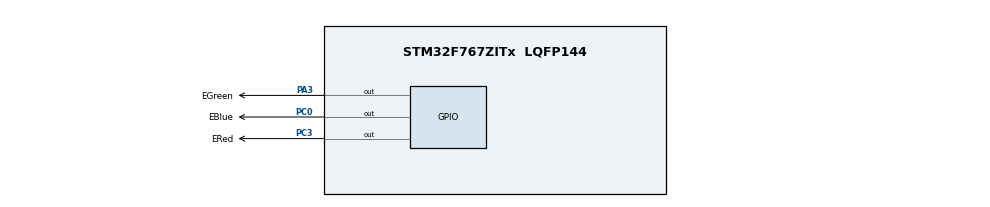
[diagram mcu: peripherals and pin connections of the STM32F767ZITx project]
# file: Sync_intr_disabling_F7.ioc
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FREERTOS.Tasks01=defaultTask,8,128,StartDefaultTask,Default,NULL,Dynamic,NULL,NULL;toggleGreen,24,128,toggleGreenHook,Default,NULL,Dynamic,NULL,NULL;toggleRed,24,128,toggleRedHook,Default,NULL,Dynamic,NULL,NULL
FREERTOS.configUSE_NEWLIB_REENTRANT=1
Mcu.Family=STM32F7
Mcu.Name=STM32F767ZITx
Mcu.Package=LQFP144
NVIC.PriorityGroup=NVIC_PRIORITYGROUP_4
NVIC.TIM1_UP_TIM10_IRQn=true\:15\:0\:false\:false\:true\:false\:false\:true\:true
NVIC.TimeBase=TIM1_UP_TIM10_IRQn
NVIC.TimeBaseIP=TIM1
PA3.GPIO_Label=EGreen
PA3.Signal=GPIO_Output
PC0.GPIO_Label=EBlue
PC0.Signal=GPIO_Output
PC3.GPIO_Label=ERed
PC3.Signal=GPIO_Output
ProjectManager.HeapSize=0x200
ProjectManager.StackSize=0x400
ProjectManager.TargetToolchain=STM32CubeIDE
RCC.HSE_VALUE=25000000
RCC.HSI_VALUE=16000000
RCC.LSE_VALUE=32768
RCC.USBFreq_Value=96000000
RCC.VCOOutputFreq_Value=192000000
VP_FREERTOS_VS_CMSIS_V2.Mode=CMSIS_V2
VP_SYS_VS_tim1.Mode=TIM1
board=custom

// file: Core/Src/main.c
/* USER CODE BEGIN Header */
/**
  ******************************************************************************
  * @file           : main.c
  * @brief          : Main program body
  ******************************************************************************
  * @attention
  *
  * Copyright (c) 2023 STMicroelectronics.
  * All rights reserved.
  *
  * This software is licensed under terms that can be found in the LICENSE file
  * in the root directory of this software component.
  * If no LICENSE file comes with this software, it is provided AS-IS.
  *
  ******************************************************************************
  */
/* USER CODE END Header */
#include "main.h"
#include "cmsis_os.h"

/* Definitions for defaultTask */
osThreadId_t defaultTaskHandle;
const osThreadAttr_t defaultTask_attributes = {
  .name = "defaultTask",
  .stack_size = 128 * 4,
  .priority = (osPriority_t) osPriorityLow,
};
/* Definitions for toggleGreen */
osThreadId_t toggleGreenHandle;
const osThreadAttr_t toggleGreen_attributes = {
  .name = "toggleGreen",
  .stack_size = 128 * 4,
  .priority = (osPriority_t) osPriorityNormal,
};
/* Definitions for toggleRed */
osThreadId_t toggleRedHandle;
const osThreadAttr_t toggleRed_attributes = {
  .name = "toggleRed",
  .stack_size = 128 * 4,
  .priority = (osPriority_t) osPriorityNormal,
};

void SystemClock_Config(void);
static void MPU_Config(void);
static void MX_GPIO_Init(void);
void StartDefaultTask(void *argument);
void toggleGreenHook(void *argument);
void toggleRedHook(void *argument);

/* USER CODE BEGIN 0 */
void shared_function();
int flag = 1;
/* USER CODE END 0 */

int main(void)
{

  /* MPU Configuration--------------------------------------------------------*/
  MPU_Config();

  /* MCU Configuration--------------------------------------------------------*/

  /* Reset of all peripherals, Initializes the Flash interface and the Systick. */
  HAL_Init();

  /* Configure the system clock */
  SystemClock_Config();

  /* Initialize all configured peripherals */
  MX_GPIO_Init();

  /* Init scheduler */
  osKernelInitialize();

  /* Create the thread(s) */
  /* creation of defaultTask */
  defaultTaskHandle = osThreadNew(StartDefaultTask, NULL, &defaultTask_attributes);

  /* creation of toggleGreen */
  toggleGreenHandle = osThreadNew(toggleGreenHook, NULL, &toggleGreen_attributes);

  /* creation of toggleRed */
  toggleRedHandle = osThreadNew(toggleRedHook, NULL, &toggleRed_attributes);

  /* Start scheduler */
  osKernelStart();

  /* We should never get here as control is now taken by the scheduler */
  /* Infinite loop */
  while (1)
  {

  }
}

void SystemClock_Config(void)
{
  RCC_OscInitTypeDef RCC_OscInitStruct = {0};
  RCC_ClkInitTypeDef RCC_ClkInitStruct = {0};

  /** Configure the main internal regulator output voltage
  */
  __HAL_RCC_PWR_CLK_ENABLE();
  __HAL_PWR_VOLTAGESCALING_CONFIG(PWR_REGULATOR_VOLTAGE_SCALE3);

  /** Initializes the RCC Oscillators according to the specified parameters
  * in the RCC_OscInitTypeDef structure.
  */
  RCC_OscInitStruct.OscillatorType = RCC_OSCILLATORTYPE_HSI;
  RCC_OscInitStruct.HSIState = RCC_HSI_ON;
  RCC_OscInitStruct.HSICalibrationValue = RCC_HSICALIBRATION_DEFAULT;
  RCC_OscInitStruct.PLL.PLLState = RCC_PLL_NONE;
  if (HAL_RCC_OscConfig(&RCC_OscInitStruct) != HAL_OK)
  {
    Error_Handler();
  }

  /** Initializes the CPU, AHB and APB buses clocks
  */
  RCC_ClkInitStruct.ClockType = RCC_CLOCKTYPE_HCLK|RCC_CLOCKTYPE_SYSCLK
                              |RCC_CLOCKTYPE_PCLK1|RCC_CLOCKTYPE_PCLK2;
  RCC_ClkInitStruct.SYSCLKSource = RCC_SYSCLKSOURCE_HSI;
  RCC_ClkInitStruct.AHBCLKDivider = RCC_SYSCLK_DIV1;
  RCC_ClkInitStruct.APB1CLKDivider = RCC_HCLK_DIV1;
  RCC_ClkInitStruct.APB2CLKDivider = RCC_HCLK_DIV1;

  if (HAL_RCC_ClockConfig(&RCC_ClkInitStruct, FLASH_LATENCY_0) != HAL_OK)
  {
    Error_Handler();
  }
}

static void MX_GPIO_Init(void)
{
  GPIO_InitTypeDef GPIO_InitStruct = {0};

  /* GPIO Ports Clock Enable */
  __HAL_RCC_GPIOC_CLK_ENABLE();
  __HAL_RCC_GPIOA_CLK_ENABLE();

  /*Configure GPIO pin Output Level */
  HAL_GPIO_WritePin(GPIOC, GPIO_PIN_0|GPIO_PIN_3, GPIO_PIN_RESET);

  /*Configure GPIO pin Output Level */
  HAL_GPIO_WritePin(GPIOA, GPIO_PIN_3, GPIO_PIN_RESET);

  /*Configure GPIO pins : PC0 PC3 */
  GPIO_InitStruct.Pin = GPIO_PIN_0|GPIO_PIN_3;
  GPIO_InitStruct.Mode = GPIO_MODE_OUTPUT_PP;
  GPIO_InitStruct.Pull = GPIO_NOPULL;
  GPIO_InitStruct.Speed = GPIO_SPEED_FREQ_LOW;
  HAL_GPIO_Init(GPIOC, &GPIO_InitStruct);

  /*Configure GPIO pin : PA3 */
  GPIO_InitStruct.Pin = GPIO_PIN_3;
  GPIO_InitStruct.Mode = GPIO_MODE_OUTPUT_PP;
  GPIO_InitStruct.Pull = GPIO_NOPULL;
  GPIO_InitStruct.Speed = GPIO_SPEED_FREQ_LOW;
  HAL_GPIO_Init(GPIOA, &GPIO_InitStruct);

}

/* USER CODE BEGIN 4 */
void shared_function() {
	if( flag == 1 ) {
		flag = 0;
		HAL_Delay(3000);
		flag = 1;
		HAL_GPIO_WritePin(EBlue_GPIO_Port, EBlue_Pin, GPIO_PIN_RESET);
	} else {
		// Show an alert turning the blue LED on
		HAL_GPIO_WritePin(EBlue_GPIO_Port, EBlue_Pin, GPIO_PIN_SET);
	}
}
/* USER CODE END 4 */

void StartDefaultTask(void *argument)
{
  for(;;)
  {
    osDelay(1);
  }
}

void toggleGreenHook(void *argument)
{
  /* USER CODE BEGIN toggleGreenHook */
  /* Infinite loop */
  for(;;)
  {
	  HAL_GPIO_WritePin(EGreen_GPIO_Port, EGreen_Pin, GPIO_PIN_SET);
	  HAL_Delay(3000);

	  taskENTER_CRITICAL(); // Preemptive context switches cannot occur when in a critical region. It disables interrupts.
	  shared_function();
	  taskEXIT_CRITICAL();  // End of a critical code region.
	  HAL_GPIO_WritePin(EGreen_GPIO_Port, EGreen_Pin, GPIO_PIN_RESET);
	  HAL_Delay(500);
  }
  /* USER CODE END toggleGreenHook */
}

void toggleRedHook(void *argument)
{
  /* USER CODE BEGIN toggleRedHook */
  /* Infinite loop */
  for(;;)
  {
	  HAL_GPIO_WritePin(ERed_GPIO_Port, ERed_Pin, GPIO_PIN_SET);
	  HAL_Delay(1000);
	  taskENTER_CRITICAL(); // Preemptive context switches cannot occur when in a critical region.
	  shared_function();
	  taskEXIT_CRITICAL();  // End of a critical code region.
	  HAL_GPIO_WritePin(ERed_GPIO_Port, ERed_Pin, GPIO_PIN_RESET);
	  HAL_Delay(500);
  }
  /* USER CODE END toggleRedHook */
}

/* MPU Configuration */

void MPU_Config(void)
{
  MPU_Region_InitTypeDef MPU_InitStruct = {0};

  /* Disables the MPU */
  HAL_MPU_Disable();

  /** Initializes and configures the Region and the memory to be protected
  */
  MPU_InitStruct.Enable = MPU_REGION_ENABLE;
  MPU_InitStruct.Number = MPU_REGION_NUMBER0;
  MPU_InitStruct.BaseAddress = 0x0;
  MPU_InitStruct.Size = MPU_REGION_SIZE_4GB;
  MPU_InitStruct.SubRegionDisable = 0x87;
  MPU_InitStruct.TypeExtField = MPU_TEX_LEVEL0;
  MPU_InitStruct.AccessPermission = MPU_REGION_NO_ACCESS;
  MPU_InitStruct.DisableExec = MPU_INSTRUCTION_ACCESS_DISABLE;
  MPU_InitStruct.IsShareable = MPU_ACCESS_SHAREABLE;
  MPU_InitStruct.IsCacheable = MPU_ACCESS_NOT_CACHEABLE;
  MPU_InitStruct.IsBufferable = MPU_ACCESS_NOT_BUFFERABLE;

  HAL_MPU_ConfigRegion(&MPU_InitStruct);
  /* Enables the MPU */
  HAL_MPU_Enable(MPU_PRIVILEGED_DEFAULT);

}

void HAL_TIM_PeriodElapsedCallback(TIM_HandleTypeDef *htim)
{
  if (htim->Instance == TIM1) {
    HAL_IncTick();
  }
}

void Error_Handler(void)
{
  __disable_irq();
  while (1)
  {
  }
}
